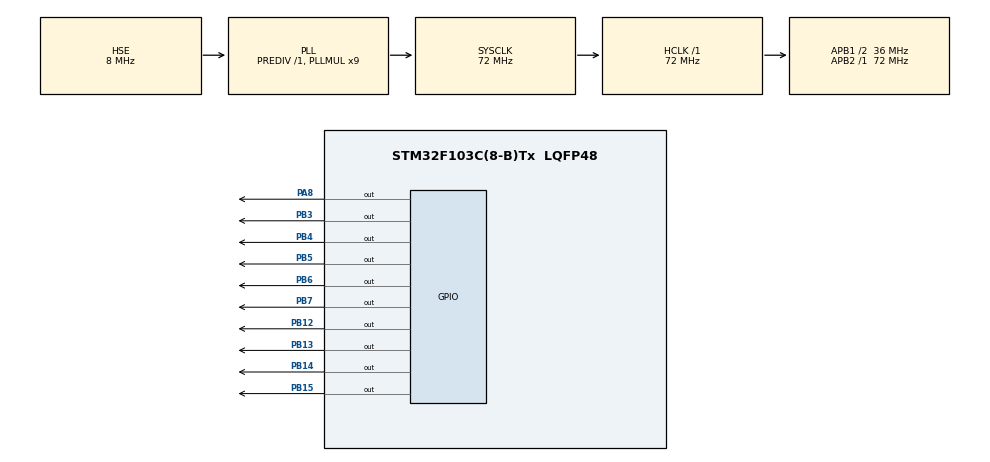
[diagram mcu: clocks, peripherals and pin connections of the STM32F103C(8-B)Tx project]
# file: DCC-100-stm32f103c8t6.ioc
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Mcu.Family=STM32F1
Mcu.Name=STM32F103C(8-B)Tx
Mcu.Package=LQFP48
NVIC.PriorityGroup=NVIC_PRIORITYGROUP_4
NVIC.TIM2_IRQn=true\:0\:0\:false\:false\:true\:true\:true\:true
PA13.Mode=Serial_Wire
PA13.Signal=SYS_JTMS-SWDIO
PA14.Mode=Serial_Wire
PA14.Signal=SYS_JTCK-SWCLK
PA8.GPIO_Speed=GPIO_SPEED_FREQ_HIGH
PA8.PinState=GPIO_PIN_SET
PA8.Signal=GPIO_Output
PB12.GPIO_Speed=GPIO_SPEED_FREQ_HIGH
PB12.PinState=GPIO_PIN_SET
PB12.Signal=GPIO_Output
PB13.GPIO_Speed=GPIO_SPEED_FREQ_HIGH
PB13.PinState=GPIO_PIN_SET
PB13.Signal=GPIO_Output
PB14.GPIO_Speed=GPIO_SPEED_FREQ_HIGH
PB14.PinState=GPIO_PIN_SET
PB14.Signal=GPIO_Output
PB15.GPIO_Speed=GPIO_SPEED_FREQ_HIGH
PB15.PinState=GPIO_PIN_SET
PB15.Signal=GPIO_Output
PB3.GPIO_Speed=GPIO_SPEED_FREQ_HIGH
PB3.PinState=GPIO_PIN_SET
PB3.Signal=GPIO_Output
PB4.GPIO_Speed=GPIO_SPEED_FREQ_HIGH
PB4.PinState=GPIO_PIN_SET
PB4.Signal=GPIO_Output
PB5.GPIO_Speed=GPIO_SPEED_FREQ_HIGH
PB5.PinState=GPIO_PIN_SET
PB5.Signal=GPIO_Output
PB6.GPIO_Speed=GPIO_SPEED_FREQ_HIGH
PB6.PinState=GPIO_PIN_SET
PB6.Signal=GPIO_Output
PB7.GPIO_Speed=GPIO_SPEED_FREQ_HIGH
PB7.PinState=GPIO_PIN_SET
PB7.Signal=GPIO_Output
PD0-OSC_IN.Mode=HSE-External-Oscillator
PD0-OSC_IN.Signal=RCC_OSC_IN
PD1-OSC_OUT.Mode=HSE-External-Oscillator
PD1-OSC_OUT.Signal=RCC_OSC_OUT
ProjectManager.HeapSize=0x200
ProjectManager.StackSize=0x400
ProjectManager.TargetToolchain=MDK-ARM V5
RCC.AHBFreq_Value=72000000
RCC.APB1CLKDivider=RCC_HCLK_DIV2
RCC.APB1Freq_Value=36000000
RCC.APB1TimFreq_Value=72000000
RCC.APB2Freq_Value=72000000
RCC.APB2TimFreq_Value=72000000
RCC.HCLKFreq_Value=72000000
RCC.PLLMUL=RCC_PLL_MUL9
RCC.PLLSourceVirtual=RCC_PLLSOURCE_HSE
RCC.SYSCLKFreq_VALUE=72000000
RCC.SYSCLKSource=RCC_SYSCLKSOURCE_PLLCLK
RCC.USBFreq_Value=72000000
TIM2.AutoReloadPreload=TIM_AUTORELOAD_PRELOAD_DISABLE
TIM2.Period=360
TIM2.Prescaler=0
VP_TIM2_VS_ClockSourceINT.Mode=Internal
board=custom

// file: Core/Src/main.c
/* USER CODE BEGIN Header */
/**
  ******************************************************************************
  * @file           : main.c
  * @brief          : Main program body
  ******************************************************************************
  * @attention
  *
  * Copyright (c) 2025 STMicroelectronics.
  * All rights reserved.
  *
  * This software is licensed under terms that can be found in the LICENSE file
  * in the root directory of this software component.
  * If no LICENSE file comes with this software, it is provided AS-IS.
  *
  ******************************************************************************
  */
#include "motor.h"
/* USER CODE END Header */
#include "main.h"
#include "tim.h"
#include "gpio.h"

void SystemClock_Config(void);

int main(void)
{

  /* MCU Configuration--------------------------------------------------------*/

  /* Reset of all peripherals, Initializes the Flash interface and the Systick. */
  HAL_Init();

  /* Configure the system clock */
  SystemClock_Config();

  /* Initialize all configured peripherals */
  MX_GPIO_Init();
  MX_TIM2_Init();
  /* USER CODE BEGIN 2 */

  HAL_TIM_Base_Start_IT(&htim2);

  /* USER CODE END 2 */

  /* Infinite loop */
  /* USER CODE BEGIN WHILE */
  while (1)
  {
    Motor_Init();

    // // 单电机测试
    // Motor_SetDirection(1, 1); // 上下电机正转
    // Motor_SetSpeed(1, 270); // 上下电机速度
    // Motor_Start(1); // 启动上下电机
    // // Motor_Turn_Angle(1, 270); // 上下电机转动
    // HAL_Delay(5000);

    // 双电机测试
    Motor_SetSpeed(1, 10);
    Motor_SetSpeed(0, 10);
    Motor_SetDirection(1, 1); // 上下电机正转
    Motor_SetDirection(0, 0); // 左右电机反转
    Motor_Turn_Angle(1, 30); // 上下电机转动
    Motor_Turn_Angle(0, 30); // 左右电机转动
    HAL_Delay(8000);
    Motor_SetDirection(1, 0); // 上下电机反转
    Motor_SetDirection(0, 1); // 左右电机正转
    Motor_Turn_Angle(1, 30); // 上下电机转动
    Motor_Turn_Angle(0, 30); // 左右电机转动
    HAL_Delay(8000);

    /* USER CODE END WHILE */

  }
}

void SystemClock_Config(void)
{
  RCC_OscInitTypeDef RCC_OscInitStruct = {0};
  RCC_ClkInitTypeDef RCC_ClkInitStruct = {0};

  /** Initializes the RCC Oscillators according to the specified parameters
  * in the RCC_OscInitTypeDef structure.
  */
  RCC_OscInitStruct.OscillatorType = RCC_OSCILLATORTYPE_HSE;
  RCC_OscInitStruct.HSEState = RCC_HSE_ON;
  RCC_OscInitStruct.HSEPredivValue = RCC_HSE_PREDIV_DIV1;
  RCC_OscInitStruct.HSIState = RCC_HSI_ON;
  RCC_OscInitStruct.PLL.PLLState = RCC_PLL_ON;
  RCC_OscInitStruct.PLL.PLLSource = RCC_PLLSOURCE_HSE;
  RCC_OscInitStruct.PLL.PLLMUL = RCC_PLL_MUL9;
  if (HAL_RCC_OscConfig(&RCC_OscInitStruct) != HAL_OK)
  {
    Error_Handler();
  }

  /** Initializes the CPU, AHB and APB buses clocks
  */
  RCC_ClkInitStruct.ClockType = RCC_CLOCKTYPE_HCLK|RCC_CLOCKTYPE_SYSCLK
                              |RCC_CLOCKTYPE_PCLK1|RCC_CLOCKTYPE_PCLK2;
  RCC_ClkInitStruct.SYSCLKSource = RCC_SYSCLKSOURCE_PLLCLK;
  RCC_ClkInitStruct.AHBCLKDivider = RCC_SYSCLK_DIV1;
  RCC_ClkInitStruct.APB1CLKDivider = RCC_HCLK_DIV2;
  RCC_ClkInitStruct.APB2CLKDivider = RCC_HCLK_DIV1;

  if (HAL_RCC_ClockConfig(&RCC_ClkInitStruct, FLASH_LATENCY_2) != HAL_OK)
  {
    Error_Handler();
  }
}

void Error_Handler(void)
{
  __disable_irq();
  while (1)
  {
  }
}
